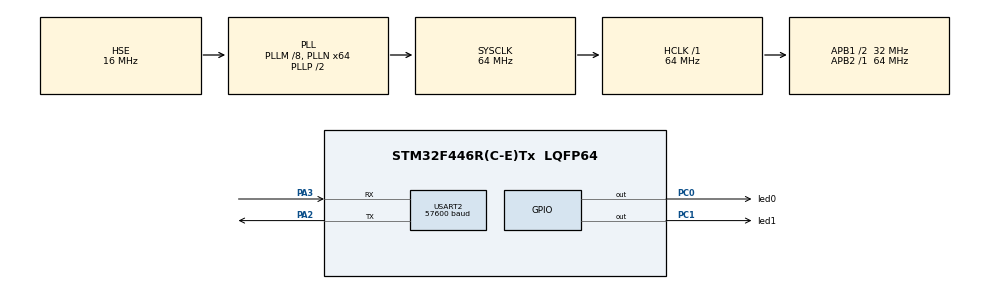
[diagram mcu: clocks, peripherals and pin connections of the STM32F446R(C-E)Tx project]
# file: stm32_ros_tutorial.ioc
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Dma.Request0=USART2_RX
Dma.Request1=USART2_TX
Dma.USART2_RX.0.Direction=DMA_PERIPH_TO_MEMORY
Dma.USART2_RX.0.FIFOMode=DMA_FIFOMODE_DISABLE
Dma.USART2_RX.0.Instance=DMA1_Stream5
Dma.USART2_RX.0.MemDataAlignment=DMA_MDATAALIGN_BYTE
Dma.USART2_RX.0.MemInc=DMA_MINC_ENABLE
Dma.USART2_RX.0.Mode=DMA_CIRCULAR
Dma.USART2_RX.0.PeriphDataAlignment=DMA_PDATAALIGN_BYTE
Dma.USART2_RX.0.PeriphInc=DMA_PINC_DISABLE
Dma.USART2_RX.0.Priority=DMA_PRIORITY_HIGH
Dma.USART2_TX.1.Direction=DMA_MEMORY_TO_PERIPH
Dma.USART2_TX.1.FIFOMode=DMA_FIFOMODE_DISABLE
Dma.USART2_TX.1.Instance=DMA1_Stream6
Dma.USART2_TX.1.MemDataAlignment=DMA_MDATAALIGN_BYTE
Dma.USART2_TX.1.MemInc=DMA_MINC_ENABLE
Dma.USART2_TX.1.Mode=DMA_NORMAL
Dma.USART2_TX.1.PeriphDataAlignment=DMA_PDATAALIGN_BYTE
Dma.USART2_TX.1.PeriphInc=DMA_PINC_DISABLE
Dma.USART2_TX.1.Priority=DMA_PRIORITY_HIGH
Mcu.Family=STM32F4
Mcu.Name=STM32F446R(C-E)Tx
Mcu.Package=LQFP64
NVIC.DMA1_Stream5_IRQn=true\:0\:0\:false\:false\:true\:false\:true
NVIC.DMA1_Stream6_IRQn=true\:0\:0\:false\:false\:true\:false\:true
NVIC.PriorityGroup=NVIC_PRIORITYGROUP_4
NVIC.USART2_IRQn=true\:0\:0\:false\:false\:true\:true\:true
PA13.Mode=Serial_Wire
PA13.Signal=SYS_JTMS-SWDIO
PA14.Mode=Serial_Wire
PA14.Signal=SYS_JTCK-SWCLK
PA2.Mode=Asynchronous
PA2.Signal=USART2_TX
PA3.Mode=Asynchronous
PA3.Signal=USART2_RX
PC0.GPIO_Label=led0
PC0.Signal=GPIO_Output
PC1.GPIO_Label=led1
PC1.Signal=GPIO_Output
PH0-OSC_IN.Mode=HSE-External-Oscillator
PH0-OSC_IN.Signal=RCC_OSC_IN
PH1-OSC_OUT.Mode=HSE-External-Oscillator
PH1-OSC_OUT.Signal=RCC_OSC_OUT
ProjectManager.HeapSize=0x200
ProjectManager.StackSize=0x400
ProjectManager.TargetToolchain=STM32CubeIDE
RCC.AHBFreq_Value=64000000
RCC.APB1CLKDivider=RCC_HCLK_DIV2
RCC.APB1Freq_Value=32000000
RCC.APB1TimFreq_Value=64000000
RCC.APB2Freq_Value=64000000
RCC.APB2TimFreq_Value=64000000
RCC.CortexFreq_Value=64000000
RCC.HCLKFreq_Value=64000000
RCC.HSE_VALUE=16000000
RCC.PLLM=8
RCC.PLLN=64
RCC.PLLSourceVirtual=RCC_PLLSOURCE_HSE
RCC.SYSCLKFreq_VALUE=64000000
RCC.SYSCLKSource=RCC_SYSCLKSOURCE_PLLCLK
RCC.USBFreq_Value=64000000
RCC.VCOOutputFreq_Value=128000000
TIM2.Period=0xffffffff
TIM2.Prescaler=64000-1
USART2.BaudRate=57600
USART2.VirtualMode=VM_ASYNC
VP_TIM2_VS_ClockSourceINT.Mode=Internal
board=custom

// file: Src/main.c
/* USER CODE BEGIN Header */
/**
  ******************************************************************************
  * @file           : main.c
  * @brief          : Main program body
  ******************************************************************************
  * @attention
  *
  * <h2><center>&copy; Copyright (c) 2020 STMicroelectronics.
  * All rights reserved.</center></h2>
  *
  * This software component is licensed by ST under BSD 3-Clause license,
  * the "License"; You may not use this file except in compliance with the
  * License. You may obtain a copy of the License at:
  *                        opensource.org/licenses/BSD-3-Clause
  *
  ******************************************************************************
  */
/* USER CODE END Header */

#include "main.h"
#include "dma.h"
#include "tim.h"
#include "usart.h"
#include "gpio.h"

void SystemClock_Config(void);

int main(void)
{

  /* MCU Configuration--------------------------------------------------------*/

  /* Reset of all peripherals, Initializes the Flash interface and the Systick. */
  HAL_Init();

  /* Configure the system clock */
  SystemClock_Config();

  /* Initialize all configured peripherals */
  MX_GPIO_Init();
  MX_DMA_Init();
  MX_TIM2_Init();
  MX_USART2_UART_Init();
  /* USER CODE BEGIN 2 */
  uint8_t txdata[] = "hello world!";

  setup();
  /* USER CODE END 2 */

  /* Infinite loop */
  while (1)
  {

    /* USER CODE BEGIN 3 */

//	  if(nowTick - pastTick > 1000)
//	  {
//		  HAL_GPIO_TogglePin(GPIOC, GPIO_PIN_0 | GPIO_PIN_1);

//		  HAL_UART_Transmit_IT(&huart2, txdata, sizeof(txdata));
//		  pastTick = nowTick;
//	  }

	loop();

  }
  /* USER CODE END 3 */
}

void SystemClock_Config(void)
{
  RCC_OscInitTypeDef RCC_OscInitStruct = {0};
  RCC_ClkInitTypeDef RCC_ClkInitStruct = {0};

  /** Configure the main internal regulator output voltage
  */
  __HAL_RCC_PWR_CLK_ENABLE();
  __HAL_PWR_VOLTAGESCALING_CONFIG(PWR_REGULATOR_VOLTAGE_SCALE3);
  /** Initializes the CPU, AHB and APB busses clocks
  */
  RCC_OscInitStruct.OscillatorType = RCC_OSCILLATORTYPE_HSE;
  RCC_OscInitStruct.HSEState = RCC_HSE_ON;
  RCC_OscInitStruct.PLL.PLLState = RCC_PLL_ON;
  RCC_OscInitStruct.PLL.PLLSource = RCC_PLLSOURCE_HSE;
  RCC_OscInitStruct.PLL.PLLM = 8;
  RCC_OscInitStruct.PLL.PLLN = 64;
  RCC_OscInitStruct.PLL.PLLP = RCC_PLLP_DIV2;
  RCC_OscInitStruct.PLL.PLLQ = 2;
  RCC_OscInitStruct.PLL.PLLR = 2;
  if (HAL_RCC_OscConfig(&RCC_OscInitStruct) != HAL_OK)
  {
    Error_Handler();
  }
  /** Initializes the CPU, AHB and APB busses clocks
  */
  RCC_ClkInitStruct.ClockType = RCC_CLOCKTYPE_HCLK|RCC_CLOCKTYPE_SYSCLK
                              |RCC_CLOCKTYPE_PCLK1|RCC_CLOCKTYPE_PCLK2;
  RCC_ClkInitStruct.SYSCLKSource = RCC_SYSCLKSOURCE_PLLCLK;
  RCC_ClkInitStruct.AHBCLKDivider = RCC_SYSCLK_DIV1;
  RCC_ClkInitStruct.APB1CLKDivider = RCC_HCLK_DIV2;
  RCC_ClkInitStruct.APB2CLKDivider = RCC_HCLK_DIV1;

  if (HAL_RCC_ClockConfig(&RCC_ClkInitStruct, FLASH_LATENCY_2) != HAL_OK)
  {
    Error_Handler();
  }
}

void Error_Handler(void)
{
}

/************************ (C) COPYRIGHT STMicroelectronics *****END OF FILE****/
